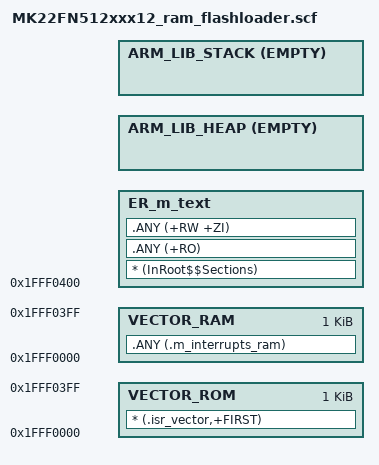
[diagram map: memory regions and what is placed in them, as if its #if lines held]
#!armclang --target=arm-arm-none-eabi -mcpu=cortex-m4 -E -x c
/*
** ###################################################################
**     Processors:          MK22FN512CAP12
**                          MK22FN512VDC12
**                          MK22FN512VFX12
**                          MK22FN512VLH12
**                          MK22FN512VLL12
**                          MK22FN512VMP12
**
**     Compiler:            Keil ARM C/C++ Compiler
**
**     Abstract:
**         Linker file for the Keil ARM C/C++ Compiler
**
**     Copyright (c) 2015 Freescale Semiconductor, Inc.
**     Copyright 2016-2018 NXP
**     All rights reserved.
**
**     SPDX-License-Identifier: BSD-3-Clause
**
**     http:                 www.nxp.com
**     mail:                 support@nxp.com
**
** ###################################################################
*/

#define m_interrupts_start             0x1FFF0000
#define m_interrupts_size              0x00000400

#define m_text_start                   0x1FFF0400
#define m_text_size                    0x0001FC00

/* Sizes */
#if (defined(__stack_size__))
  #define Stack_Size                   __stack_size__
#else
  #define Stack_Size                   0x1000
#endif

#if (defined(__heap_size__))
  #define Heap_Size                    __heap_size__
#else
  #define Heap_Size                    0x0
#endif

LR_m_text m_text_start m_text_size {   ; load region size_region
  ER_m_text m_text_start m_text_size - Stack_Size-Heap_Size{ ; load address = execution address
    * (InRoot$$Sections)
    .ANY (+RO)
    .ANY (+RW +ZI)
  }
  ARM_LIB_HEAP (ImageLimit(ER_m_text)) EMPTY Heap_Size {    ; Heap region growing up
  }
  ARM_LIB_STACK (ImageLimit(ARM_LIB_HEAP) + Stack_Size) EMPTY -Stack_Size { ; Stack region growing down
  }
}

LR_m_interrupts m_interrupts_start m_interrupts_size {
  VECTOR_ROM m_interrupts_start m_interrupts_size { ; load address = execution address
    * (.isr_vector,+FIRST)
  }
}

LR_m_interrupts_ram m_interrupts_start m_interrupts_size {
  VECTOR_RAM m_interrupts_start m_interrupts_size { ; load address = execution address
    .ANY (.m_interrupts_ram)
  }
}

